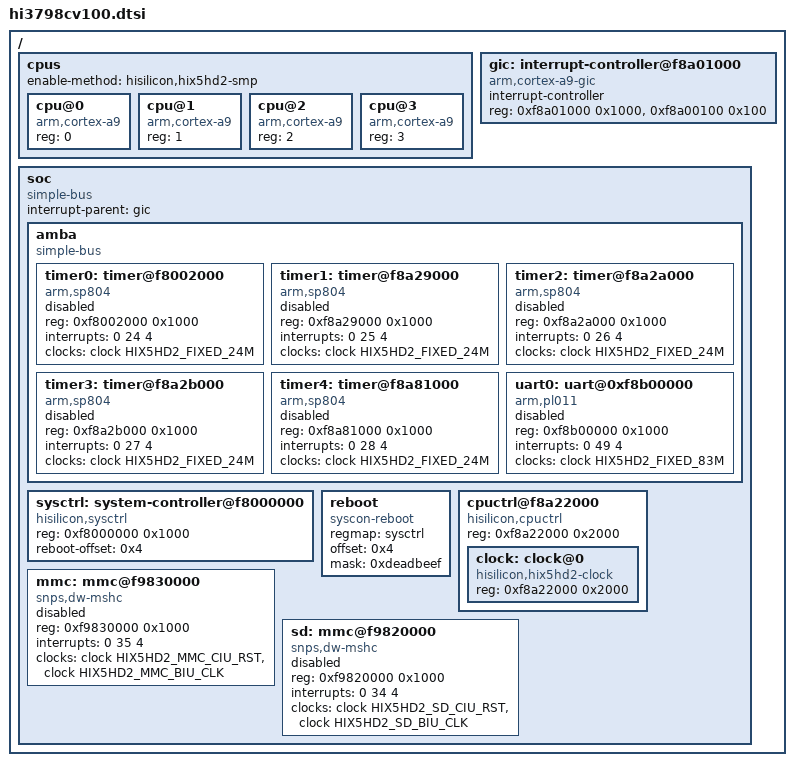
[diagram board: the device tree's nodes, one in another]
/*
 * Copyright (c) 2013-2014 Linaro Ltd.
 * Copyright (c) 2013-2014 Hisilicon Limited.
 *
 * This program is free software; you can redistribute it and/or modify
 * it under the terms of the GNU General Public License version 2 as
 * publishhed by the Free Software Foundation.
 */

#include "skeleton.dtsi"
#include <dt-bindings/clock/hix5hd2-clock.h>

/ {
        cpus {
                #address-cells = <1>;
                #size-cells = <0>;
                enable-method = "hisilicon,hix5hd2-smp";

                cpu@0 {
                        compatible = "arm,cortex-a9";
                        device_type = "cpu";
                        reg = <0>;
                        /*next-level-cache = <&l2>;*/
                };

                cpu@1 {
                        compatible = "arm,cortex-a9";
                        device_type = "cpu";
                        reg = <1>;
                        /*next-level-cache = <&l2>;*/
                };

                cpu@2 {
                        compatible = "arm,cortex-a9";
                        device_type = "cpu";
                        reg = <2>;
                        /*next-level-cache = <&l2>;*/
                };

                cpu@3 {
                        compatible = "arm,cortex-a9";
                        device_type = "cpu";
                        reg = <3>;
                        /*next-level-cache = <&l2>;*/
                };
	};

	gic: interrupt-controller@f8a01000 {
		compatible = "arm,cortex-a9-gic";
		#interrupt-cells = <3>;
		#address-cells = <0>;
		interrupt-controller;
		/* gic dist base, gic cpu base */
		reg = <0xf8a01000 0x1000>, <0xf8a00100 0x100>;
	};
	
	soc {
		#address-cells = <1>;
		#size-cells = <1>;
		compatible = "simple-bus";
		interrupt-parent = <&gic>;
		/*ranges = <0 0xf8000000 0x8000000>;*/
		ranges = <0x0 0x0 0xffffffff>;

		amba {
			#address-cells = <1>;
			#size-cells = <1>;
			compatible = "simple-bus";
			ranges;

			timer0: timer@f8002000 {
				compatible = "arm,sp804", "arm,primecell";
				reg = <0xf8002000 0x1000>;
				/* timer00 & timer01 */
				interrupts = <0 24 4>;
				/*clocks = <&xtal_clk>;*/
				clocks = <&clock HIX5HD2_FIXED_24M>;
				status = "disabled";
			};
			
			timer1: timer@f8a29000 {
				/*
				 * Only used in NORMAL state, not available ins
				 * SLOW or DOZE state.
				 * The rate is fixed in 24MHz.
				 */
				compatible = "arm,sp804", "arm,primecell";
				reg = <0xf8a29000 0x1000>;
				/* timer10 & timer11 */
				interrupts = <0 25 4>;
				clocks = <&clock HIX5HD2_FIXED_24M>;
				status = "disabled";
			};

			timer2: timer@f8a2a000 {
				compatible = "arm,sp804", "arm,primecell";
				reg = <0xf8a2a000 0x1000>;
				/* timer20 & timer21 */
				interrupts = <0 26 4>;
				clocks = <&clock HIX5HD2_FIXED_24M>;
				status = "disabled";
			};

			timer3: timer@f8a2b000 {
				compatible = "arm,sp804", "arm,primecell";
				reg = <0xf8a2b000 0x1000>;
				/* timer30 & timer31 */
				interrupts = <0 27 4>;
				clocks = <&clock HIX5HD2_FIXED_24M>;
				status = "disabled";
			};

			timer4: timer@f8a81000 {
				compatible = "arm,sp804", "arm,primecell";
				reg = <0xf8a81000 0x1000>;
				/* timer30 & timer31 */
				interrupts = <0 28 4>;
				clocks = <&clock HIX5HD2_FIXED_24M>;
				status = "disabled";
			};

			uart0: uart@0xf8b00000 {
				compatible = "arm,pl011", "arm,primecell";
				reg = <0xf8b00000 0x1000>;
				interrupts = <0 49 4>;
				/*clocks = <&clk_83p3m>;*/
				clocks = <&clock HIX5HD2_FIXED_83M>;
				clock-names = "apb_pclk";
				status = "disabled";
			};
		};

/*
		l2: l2-cache {
			compatible = "arm,pl310-cache";
			reg = <0xf8a10000 0x100000>;
			interrupts = <0 15 4>;
			cache-unified;
			cache-level = <2>;
		};
*/

		sysctrl: system-controller@f8000000 {
			compatible = "hisilicon,sysctrl", "syscon";
			reg = <0xf8000000 0x1000>;
			reboot-offset = <0x4>;
		};

		reboot {
			compatible = "syscon-reboot";
			regmap = <&sysctrl>;
			offset = <0x4>;
			mask = <0xdeadbeef>;
		};

		cpuctrl@f8a22000 {
			compatible = "hisilicon,cpuctrl";
			#address-cells = <1>;
			#size-cells = <1>;
			reg = <0xf8a22000 0x2000>;
			ranges;
			
			clock: clock@0 {
				compatible = "hisilicon,hix5hd2-clock";
				reg = <0xf8a22000 0x2000>;
				#clock-cells = <1>;
			};
		};
		
		/* unremovable emmc as mmcblk0 */
		mmc: mmc@f9830000 {
			compatible = "snps,dw-mshc";
			reg = <0xf9830000 0x1000>;
			interrupts = <0 35 4>;
			clocks = <&clock HIX5HD2_MMC_CIU_RST>,
				 <&clock HIX5HD2_MMC_BIU_CLK>;
			clock-names = "ciu", "biu";
			status = "disabled";
		};

		sd: mmc@f9820000 {
			compatible = "snps,dw-mshc";
			reg = <0xf9820000 0x1000>;
			interrupts = <0 34 4>;
			clocks = <&clock HIX5HD2_SD_CIU_RST>,
				 <&clock HIX5HD2_SD_BIU_CLK>;
			clock-names = "ciu","biu";
			status = "disabled";
		};

		
	};
};
